# AVR64DU28 device description
Architecture: AVR8X; Family: AVR
Registers are 8-bit, read-write, reset 0x0 unless marked. A register's access mark holds for its fields unless they carry their own. Offsets are from the block's base; [hi:lo] are bit positions; {n}, {i} and the like mark numbered series.

## FUSE — Fuses
Instances: FUSE 0x1050
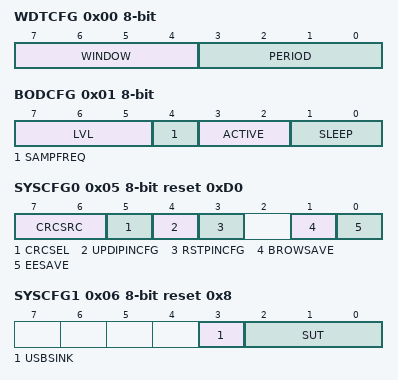
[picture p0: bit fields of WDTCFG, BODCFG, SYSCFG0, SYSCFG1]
0x00 WDTCFG — Watchdog Configuration
  [7:4] WINDOW — Watchdog Window Timeout Period
    0=OFF (Window mode off); 1=8CLK (8 cycles (8ms)); 2=16CLK (16 cycles (16ms)); 3=32CLK (32 cycles (32ms)); 4=64CLK (64 cycles (64ms)); 5=128CLK (128 cycles (0.128s)); 6=256CLK (256 cycles (0.256s)); 7=512CLK (512 cycles (0.512s)); 8=1KCLK (1K cycles (1.0s)); 9=2KCLK (2K cycles (2.0s)); 10=4KCLK (4K cycles (4.0s)); 11=8KCLK (8K cycles (8.0s))
  [3:0] PERIOD — Watchdog Timeout Period
    0=OFF (Watch-Dog timer Off); 1=8CLK (8 cycles (8ms)); 2=16CLK (16 cycles (16ms)); 3=32CLK (32 cycles (32ms)); 4=64CLK (64 cycles (64ms)); 5=128CLK (128 cycles (0.128s)); 6=256CLK (256 cycles (0.256s)); 7=512CLK (512 cycles (0.512s)); 8=1KCLK (1K cycles (1.0s)); 9=2KCLK (2K cycles (2.0s)); 10=4KCLK (4K cycles (4.0s)); 11=8KCLK (8K cycles (8.0s))
0x01 BODCFG — BOD Configuration
  [7:5] LVL — BOD Level
    0=BODLEVEL0 (1.9V); 1=BODLEVEL1 (2.45V); 2=BODLEVEL2 (2.7V); 3=BODLEVEL3 (2.85V)
  [4] SAMPFREQ — BOD Sample Frequency
    0=128Hz (Sample frequency is 128 Hz); 1=32Hz (Sample frequency is 32 Hz)
  [3:2] ACTIVE — BOD Operation in Active Mode
    0=DISABLE (BOD disabled); 1=ENABLE (BOD enabled in continuous mode); 2=SAMPLE (BOD enabled in sampled mode); 3=ENABLEWAIT (BOD enabled in continuous mode. Execution is halted at wake-up until BOD is running.)
  [1:0] SLEEP — BOD Operation in Sleep Mode
    0=DISABLE (BOD disabled); 1=ENABLE (BOD enabled in continuous mode); 2=SAMPLE (BOD enabled in sampled mode)
0x02 OSCCFG — Oscillator Configuration
  [2:0] CLKSEL — Frequency Select
    0=OSCHF (1-32MHz internal oscillator); 1=OSC32K (32.768kHz internal oscillator)
0x05 SYSCFG0 reset 0xD0 — System Configuration 0
  [7:6] CRCSRC — CRC Source
    0=FLASH (CRC of full Flash (boot, application code and application data)); 1=BOOT (CRC of boot section); 2=BOOTAPP (CRC of application code and boot sections); 3=NOCRC
  [5] CRCSEL — CRC Select
    0=CRC16 (Enable CRC16); 1=CRC32 (Enable CRC32)
  [4] UPDIPINCFG — UPDI Pin Configuration
    0=GPIO (GPIO Mode); 1=UPDI (UPDI Mode)
  [3] RSTPINCFG — Reset Pin Configuration
    0=GPIO (GPIO mode); 1=RST (Reset mode)
  [1] BROWSAVE — Boot Row Save
  [0] EESAVE — EEPROM Save
0x06 SYSCFG1 reset 0x8 — System Configuration 1
  [3] USBSINK — USB Voltage Regulator Current Sink Enable
    0=DISABLE (USB VREG can not sink current); 1=ENABLE (USB VREG can sink current)
  [2:0] SUT — Startup Time
    0=0MS; 1=1MS; 2=2MS; 3=4MS; 4=8MS; 5=16MS; 6=32MS; 7=64MS
0x07 CODESIZE — Code Section Size
0x08 BOOTSIZE — Boot Section Size
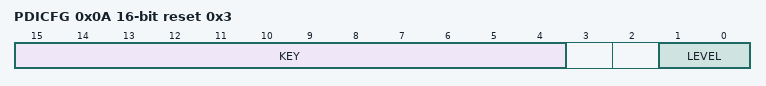
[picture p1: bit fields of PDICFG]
0x0A PDICFG 16-bit reset 0x3 — Programming and Debugging Interface Configuration
  [15:4] KEY — NVM Protection Activation Key
    0=NOTACT (Not Active); 0xB45=NVMACT (NVM Protection Active)
  [1:0] LEVEL — Protection Level
    1=NVMACCDIS (NVM Access through UPDI disabled); 3=BASIC (UPDI and UPDI pins working normally)

## GPR — General Purpose Registers
Instances: GPR 0x001C
{0x0+i} GPR{i} reset not defined (i=0..3) — General Purpose Register {i}

## LOCK — Lockbits
Instances: LOCK 0x1040
0x00 KEY 32-bit reset 0x5CC5C55C — Lock Key Bits
  [31:0] KEY — Lock Key
    0x5CC5C55C=NOLOCK (No locks); 0xA33A3AA3=RWLOCK (Read and write lock)

## NVMCTRL — Non-volatile Memory Controller
Instances: NVMCTRL 0x1000
0x00 CTRLA — Control A
  [6:0] CMD — Command
    0=NONE (No Command); 1=NOOP (No Operation); 2=FLWR (Flash Write); 8=FLPER (Flash Page Erase); 9=FLMPER2 (Flash Multi-Page Erase 2 pages); 10=FLMPER4 (Flash Multi-Page Erase 4 pages); 11=FLMPER8 (Flash Multi-Page Erase 8 pages); 12=FLMPER16 (Flash Multi-Page Erase 16 pages); 13=FLMPER32 (Flash Multi-Page Erase 32 pages); 18=EEWR (EEPROM Write); 19=EEERWR (EEPROM Erase and Write); 24=EEBER (EEPROM Byte Erase); 25=EEMBER2 (EEPROM Multi-Byte Erase 2 bytes); 26=EEMBER4 (EEPROM Multi-Byte Erase 4 bytes); 27=EEMBER8 (EEPROM Multi-Byte Erase 8 bytes); 28=EEMBER16 (EEPROM Multi-Byte Erase 16 bytes); 29=EEMBER32 (EEPROM Multi-Byte Erase 32 bytes); 32=CHER (Chip Erase Command); 48=EECHER (EEPROM Erase Command)
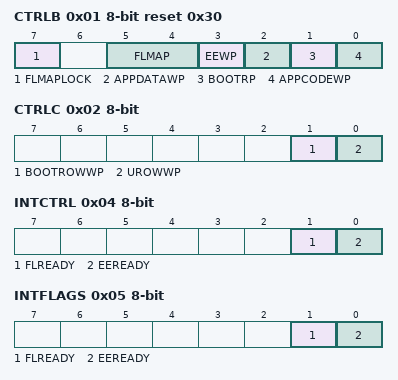
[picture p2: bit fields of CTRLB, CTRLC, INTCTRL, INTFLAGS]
0x01 CTRLB reset 0x30 — Control B
  [7] FLMAPLOCK — Flash Mapping Lock
  [5:4] FLMAP — Flash Mapping in Data space
    {v}=SECTION{v} (Flash section {v}) (v=0..3)
  [3] EEWP — EEPROM Write Protect
  [2] APPDATAWP — Application Data Write Protect
  [1] BOOTRP — Boot Read Protect
  [0] APPCODEWP — Application Code Write Protect
0x02 CTRLC — Control C
  [1] BOOTROWWP — Boot Row Write Protect
  [0] UROWWP — User Row Write Protect
0x04 INTCTRL — Interrupt Control
  [1] FLREADY — Flash Ready
  [0] EEREADY — EEPROM Ready
0x05 INTFLAGS — Interrupt Flags
  [1] FLREADY — Flash Ready
  [0] EEREADY — EEPROM Ready
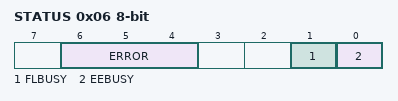
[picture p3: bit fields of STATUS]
0x06 STATUS ro
  [6:4] ERROR — Write error
    0=NOERROR; 1=INVALIDCMD (Write command not selected or not valid); 2=WRITEPROTECT (Write to section not allowed); 3=CMDCOLLISION (Selecting new write command while programming is ongoing)
  [1] FLBUSY — Flash busy
  [0] EEBUSY — EEPROM busy
0x08 DATA 32-bit
0x0C ADDR 32-bit reset not defined — Address
